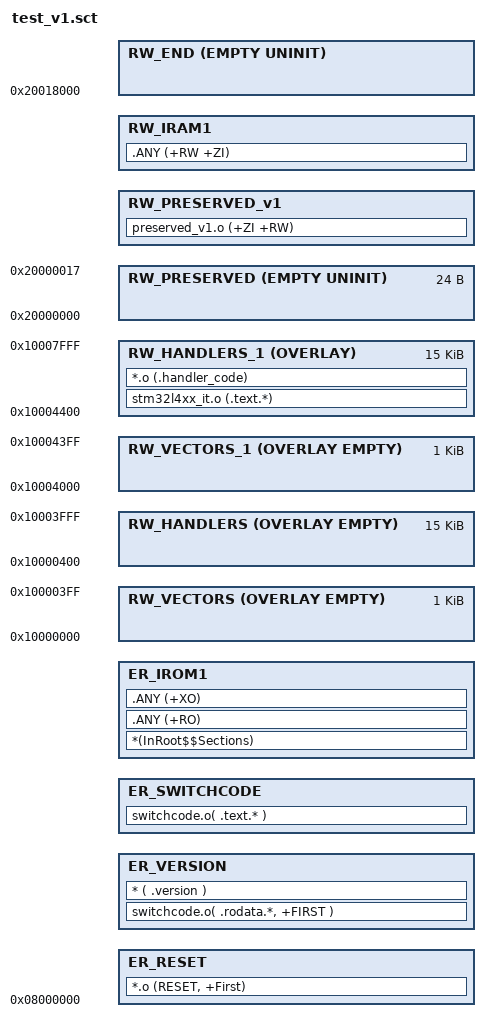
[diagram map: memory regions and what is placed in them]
; *************************************************************
; *** Scatter-Loading Description File generated by uVision ***
; *************************************************************

LR_IROM1 0x08000000 0x00080000  {    ; load region size_region
  ER_RESET 0x08000000  {  ; load address = execution address
   *.o (RESET, +First)
  }
  ER_VERSION +0
  {
;    switchcode.o( .constdata, +FIRST )
    switchcode.o( .rodata.*, +FIRST )
    * ( .version )
  }
  ER_SWITCHCODE +0   {  ; load address = execution address
;    switchcode.o( .text )
    switchcode.o( .text.* )
  }
  ER_IROM1 +0   {  ; load address = execution address
   *(InRoot$$Sections)
   .ANY (+RO)
   .ANY (+XO)
  }
  
  RW_VECTORS 0x10000000 OVERLAY EMPTY 0x00000400 {
  }
  RW_HANDLERS 0x10000400 OVERLAY EMPTY 0x00003C00 {
  }
  RW_VECTORS_1 0x10004000 OVERLAY EMPTY 0x00000400 {
  }
  RW_HANDLERS_1 0x10004400 OVERLAY 0x00003C00 {
    stm32l4xx_it.o (.text.*)
    *.o (.handler_code)
  }

  RW_PRESERVED 0x20000000 EMPTY UNINIT 0x00000018  {
  }
  RW_PRESERVED_v1 +0    {
    preserved_v1.o (+ZI +RW)
  }
  RW_IRAM1 +0   {  ; RW data
   .ANY (+RW +ZI)
  }
  RW_END 0x20018000 EMPTY UNINIT 0
  {
  }
}

